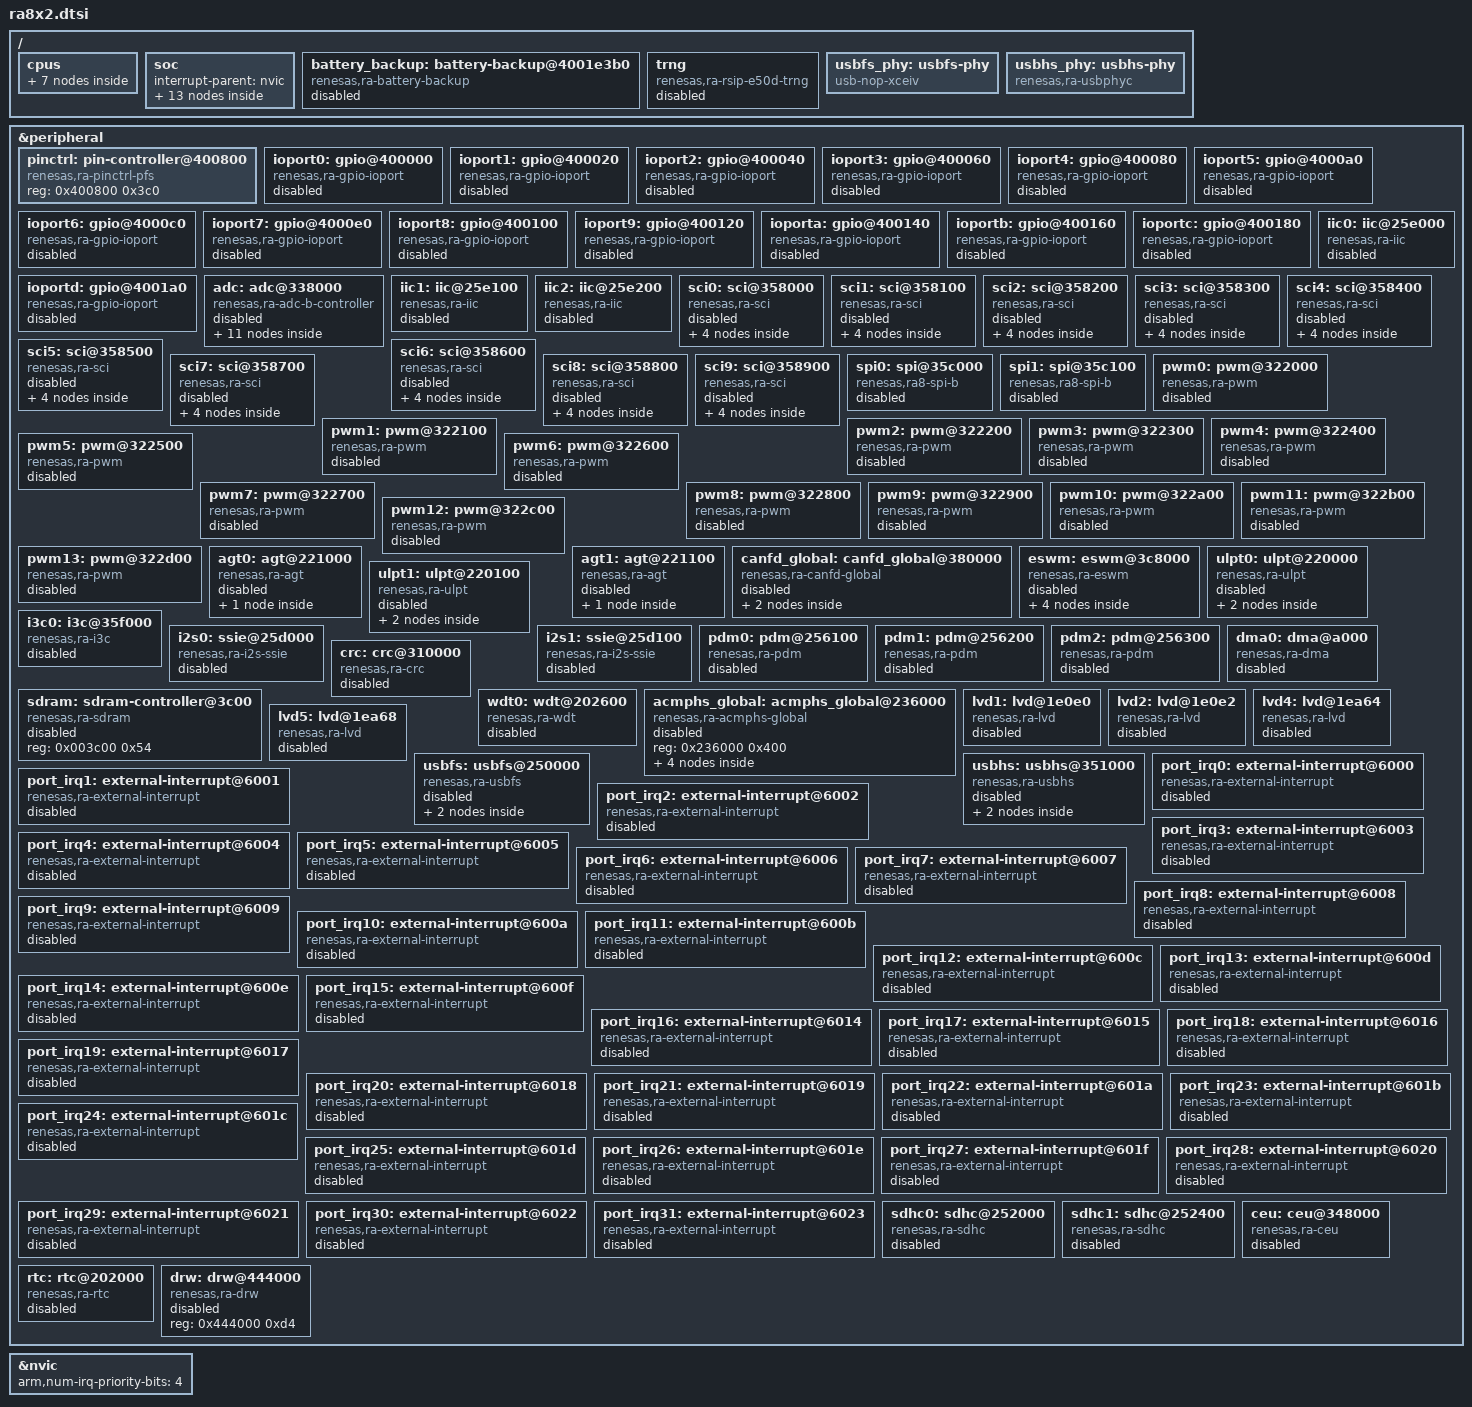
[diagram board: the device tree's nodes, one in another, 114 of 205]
/*
 * Copyright (c) 2025 Renesas Electronics Corporation
 *
 * SPDX-License-Identifier: Apache-2.0
 */

#include <mem.h>
#include <freq.h>
#include <zephyr/dt-bindings/pinctrl/renesas/pinctrl-ra.h>
#include <zephyr/dt-bindings/clock/ra_clock.h>
#include <zephyr/dt-bindings/pwm/ra_pwm.h>
#include <zephyr/dt-bindings/i2c/i2c.h>
#include <zephyr/dt-bindings/adc/renesas-adc-b.h>

/ {
	cpus {
		#address-cells = <1>;
		#size-cells = <0>;

		cpu0: cpu@0 {
			device_type = "cpu";
			compatible = "arm,cortex-m85";
			reg = <0>;
			#address-cells = <1>;
			#size-cells = <1>;
			cpu-power-states = <&stop0 &stop1>;

			mpu: mpu@e000ed90 {
				compatible = "arm,armv8.1m-mpu";
				reg = <0xe000ed90 0x40>;
			};
		};

		cpu1: cpu@1 {
			device_type = "cpu";
			compatible = "arm,cortex-m33";
			reg = <1>;
			#address-cells = <1>;
			#size-cells = <1>;

			mpu: mpu@e000ed90 {
				compatible = "arm,armv8m-mpu";
				reg = <0xe000ed90 0x40>;
			};
		};

		power-states {
			stop0: state0 {
				compatible = "zephyr,power-state";
				power-state-name = "runtime-idle";
				min-residency-us = <100>;
			};

			stop1: state1 {
				compatible = "zephyr,power-state";
				power-state-name = "standby";
				min-residency-us = <5000>;
				exit-latency-us = <3000>;
			};
		};
	};

	soc {
		interrupt-parent = <&nvic>;

		option_setting_ofs_conf_sec: option-setting-ofs-conf-sec@2c9f040 {
			reg = <0x02c9f040 0x3c0>;
			#address-cells = <1>;
			#size-cells = <1>;
			status = "okay";

			option_setting_ofs0: option-setting-ofs0@2c9f040 {
				compatible = "zephyr,memory-region";
				zephyr,memory-region = "OFS_OFS0_MEMORY";
				reg = <0x02c9f040 0x4>;
				status = "okay";
			};

			option_setting_ofs2: option-setting-ofs2@2c9f044 {
				compatible = "zephyr,memory-region";
				zephyr,memory-region = "OFS_OFS2_MEMORY";
				reg = <0x02c9f044 0x4>;
				status = "okay";
			};

			option_setting_sas: option-setting-sas@2c9f074 {
				compatible = "zephyr,memory-region";
				zephyr,memory-region = "OFS_SAS_MEMORY";
				reg = <0x02c9f074 0x4>;
				status = "okay";
			};

			option_setting_ofs1_sec: option-setting-ofs1-sec@2c9f0c0 {
				compatible = "zephyr,memory-region";
				zephyr,memory-region = "OFS_OFS1_SEC_MEMORY";
				reg = <0x02c9f0c0 0x4>;
				status = "okay";
			};

			option_setting_ofs3_sec: option-setting-ofs3-sec@2c9f0c4 {
				compatible = "zephyr,memory-region";
				zephyr,memory-region = "OFS_OFS3_SEC_MEMORY";
				reg = <0x02c9f0c4 0x4>;
				status = "okay";
			};

			option_setting_ofs1_sel: option-setting-ofs1-sel@2c9f120 {
				compatible = "zephyr,memory-region";
				zephyr,memory-region = "OFS_OFS1_SEL_MEMORY";
				reg = <0x02c9f120 0x4>;
				status = "okay";
			};

			option_setting_ofs3_sel: option-setting-ofs3-sel@2c9f124 {
				compatible = "zephyr,memory-region";
				zephyr,memory-region = "OFS_OFS3_SEL_MEMORY";
				reg = <0x02c9f124 0x4>;
				status = "okay";
			};

			option_setting_bps_sec: option-setting-bps-sec@2c9f200 {
				compatible = "zephyr,memory-region";
				zephyr,memory-region = "OFS_BPS_SEC_MEMORY";
				reg = <0x02c9f200 0x200>;
				status = "okay";
			};
		};

		option_setting_ofs_otp_sec: option-setting-ofs-otp-sec@2e07400 {
			reg = <0x02e07400 0x120a30>;
			#address-cells = <1>;
			#size-cells = <1>;
			status = "okay";

			option_setting_otp_pbps_sec: option-setting-otp-pbps-sec@2e17700 {
				compatible = "zephyr,memory-region";
				zephyr,memory-region = "OFS_OTP_PBPS_SEC_MEMORY";
				reg = <0x02e17700 0x80>;
				status = "okay";
			};
		};

		ospi0: ospi@40268000 {
			compatible = "renesas,ra-ospi-b";
			reg = <0x40268000 0x19c>, <0x80000000 DT_SIZE_M(512)>;
			unit = <0>;
			#address-cells = <1>;
			#size-cells = <0>;
			clocks = <&octaspiclk MSTPB 16>;
			status = "disabled";
		};

		ospi1: ospi@40268400 {
			compatible = "renesas,ra-ospi-b";
			reg = <0x40268400 0x19c>, <0x70000000 DT_SIZE_M(256)>;
			unit = <1>;
			#address-cells = <1>;
			#size-cells = <0>;
			clocks = <&octaspiclk MSTPB 17>;
			status = "disabled";
		};
	};

	battery_backup: battery-backup@4001e3b0 {
		compatible = "renesas,ra-battery-backup";
		reg = <0x4001e3b0 0x2>, <0x4001e3d0 0x4>,
		      <0x4001ea84 0x1>, <0x4001ea88 0x1>,
		      <0x4001ec40 0x1>, <0x4001ec45 0x1>,
		      <0x4001ec46 0x1>, <0x4001ec48 0x1>,
		      <0x4001ec49 0x1>, <0x4001ec4a 0x1>,
		      <0x4001ec4c 0x1>, <0x4001ec4d 0x1>,
		      <0x4001ec4e 0x1>, <0x4001ed00 0x80>;
		reg-names = "vbrsabar", "bbfsar",
			    "vbattmnselr", "vbtbpcr1",
			    "vbtber", "vbtbpcr2",
			    "vbtbpsr", "vbtadsr",
			    "vbtadcr1", "vbtadcr2",
			    "vbtictlr", "vbtictlr2",
			    "vbtimonr", "vbtbkrn";
		manual-configure;
		status = "disabled";
	};

	trng: trng {
		compatible = "renesas,ra-rsip-e50d-trng";
		status = "disabled";
	};

	usbfs_phy: usbfs-phy {
		compatible = "usb-nop-xceiv";
		#phy-cells = <0>;
	};

	usbhs_phy: usbhs-phy {
		compatible = "renesas,ra-usbphyc";
		#phy-cells = <0>;
	};
};

&peripheral {
	#address-cells = <1>;
	#size-cells = <1>;

	pinctrl: pin-controller@400800 {
		compatible = "renesas,ra-pinctrl-pfs";
		reg = <0x400800 0x3c0>;
		status = "okay";
	};

	ioport0: gpio@400000 {
		compatible = "renesas,ra-gpio-ioport";
		reg = <0x400000 0x20>;
		port = <0>;
		gpio-controller;
		#gpio-cells = <2>;
		ngpios = <16>;
		status = "disabled";
	};

	ioport1: gpio@400020 {
		compatible = "renesas,ra-gpio-ioport";
		reg = <0x400020 0x20>;
		port = <1>;
		gpio-controller;
		#gpio-cells = <2>;
		ngpios = <16>;
		status = "disabled";
	};

	ioport2: gpio@400040 {
		compatible = "renesas,ra-gpio-ioport";
		reg = <0x400040 0x20>;
		port = <2>;
		gpio-controller;
		#gpio-cells = <2>;
		ngpios = <16>;
		status = "disabled";
	};

	ioport3: gpio@400060 {
		compatible = "renesas,ra-gpio-ioport";
		reg = <0x400060 0x20>;
		port = <3>;
		gpio-controller;
		#gpio-cells = <2>;
		ngpios = <16>;
		status = "disabled";
	};

	ioport4: gpio@400080 {
		compatible = "renesas,ra-gpio-ioport";
		reg = <0x400080 0x20>;
		port = <4>;
		gpio-controller;
		#gpio-cells = <2>;
		ngpios = <16>;
		vbatts-pins = <2 3 4>;
		status = "disabled";
	};

	ioport5: gpio@4000a0 {
		compatible = "renesas,ra-gpio-ioport";
		reg = <0x4000a0 0x20>;
		port = <5>;
		gpio-controller;
		#gpio-cells = <2>;
		ngpios = <16>;
		status = "disabled";
	};

	ioport6: gpio@4000c0 {
		compatible = "renesas,ra-gpio-ioport";
		reg = <0x4000c0 0x20>;
		port = <6>;
		gpio-controller;
		#gpio-cells = <2>;
		ngpios = <16>;
		status = "disabled";
	};

	ioport7: gpio@4000e0 {
		compatible = "renesas,ra-gpio-ioport";
		reg = <0x4000e0 0x20>;
		port = <7>;
		gpio-controller;
		#gpio-cells = <2>;
		ngpios = <16>;
		status = "disabled";
	};

	ioport8: gpio@400100 {
		compatible = "renesas,ra-gpio-ioport";
		reg = <0x400100 0x20>;
		port = <8>;
		gpio-controller;
		#gpio-cells = <2>;
		ngpios = <16>;
		status = "disabled";
	};

	ioport9: gpio@400120 {
		compatible = "renesas,ra-gpio-ioport";
		reg = <0x400120 0x20>;
		port = <9>;
		gpio-controller;
		#gpio-cells = <2>;
		ngpios = <16>;
		status = "disabled";
	};

	ioporta: gpio@400140 {
		compatible = "renesas,ra-gpio-ioport";
		reg = <0x400140 0x20>;
		port = <10>;
		gpio-controller;
		#gpio-cells = <2>;
		ngpios = <16>;
		status = "disabled";
	};

	ioportb: gpio@400160 {
		compatible = "renesas,ra-gpio-ioport";
		reg = <0x400160 0x20>;
		port = <11>;
		gpio-controller;
		#gpio-cells = <2>;
		ngpios = <8>;
		status = "disabled";
	};

	ioportc: gpio@400180 {
		compatible = "renesas,ra-gpio-ioport";
		reg = <0x400180 0x20>;
		port = <12>;
		gpio-controller;
		#gpio-cells = <2>;
		ngpios = <16>;
		status = "disabled";
	};

	ioportd: gpio@4001a0 {
		compatible = "renesas,ra-gpio-ioport";
		reg = <0x4001a0 0x20>;
		port = <13>;
		gpio-controller;
		#gpio-cells = <2>;
		ngpios = <8>;
		status = "disabled";
	};

	adc: adc@338000 {
		compatible = "renesas,ra-adc-b-controller";
		reg = <0x338000 0x2224>;
		clocks = <&pclka MSTPD 21>;
		clock-div = <3>;
		#io-channel-cells = <1>;
		#address-cells = <1>;
		#size-cells = <0>;
		status = "disabled";

		scan_group0: scan-group@0 {
			compatible = "renesas,ra-adc-b-scan-group";
			reg = <0>;
			status = "disabled";
		};

		scan_group1: scan-group@1 {
			compatible = "renesas,ra-adc-b-scan-group";
			reg = <1>;
			status = "disabled";
		};

		scan_group2: scan-group@2 {
			compatible = "renesas,ra-adc-b-scan-group";
			reg = <2>;
			status = "disabled";
		};

		scan_group3: scan-group@3 {
			compatible = "renesas,ra-adc-b-scan-group";
			reg = <3>;
			status = "disabled";
		};

		scan_group4: scan-group@4 {
			compatible = "renesas,ra-adc-b-scan-group";
			reg = <4>;
			status = "disabled";
		};

		scan_group5: scan-group@5 {
			compatible = "renesas,ra-adc-b-scan-group";
			reg = <5>;
			status = "disabled";
		};

		scan_group6: scan-group@6 {
			compatible = "renesas,ra-adc-b-scan-group";
			reg = <6>;
			status = "disabled";
		};

		scan_group7: scan-group@7 {
			compatible = "renesas,ra-adc-b-scan-group";
			reg = <7>;
			status = "disabled";
		};

		scan_group8: scan-group@8 {
			compatible = "renesas,ra-adc-b-scan-group";
			reg = <8>;
			status = "disabled";
		};

		adc0: adc-unit0 {
			compatible = "renesas,ra-adc-b";
			unit-id = <0>;
			channel-available-mask = <0x7f503f>; /* 0-5, 12, 14, 16-22 */
			vref-mv = <3300>;
			#io-channel-cells = <1>;
			#address-cells = <1>;
			#size-cells = <0>;
			status = "disabled";
		};

		adc1: adc-unit1 {
			compatible = "renesas,ra-adc-b";
			unit-id = <1>;
			channel-available-mask = <0x7fafc0>; /* 6-11, 13, 15, 16-22 */
			vref-mv = <3300>;
			#io-channel-cells = <1>;
			#address-cells = <1>;
			#size-cells = <0>;
			status = "disabled";
		};
	};

	iic0: iic@25e000 {
		compatible = "renesas,ra-iic";
		channel = <0>;
		reg = <0x25e000 0x100>;
		clocks = <&pclkb MSTPB 9>;
		status = "disabled";
	};

	iic1: iic@25e100 {
		compatible = "renesas,ra-iic";
		channel = <1>;
		reg = <0x25e100 0x100>;
		clocks = <&pclkb MSTPB 8>;
		status = "disabled";
	};

	iic2: iic@25e200 {
		compatible = "renesas,ra-iic";
		channel = <2>;
		reg = <0x25e200 0x100>;
		clocks = <&pclkb MSTPB 7>;
		status = "disabled";
	};

	sci0: sci@358000 {
		compatible = "renesas,ra-sci";
		reg = <0x358000 0x100>;
		channel = <0>;
		clocks = <&sciclk MSTPB 31>;
		status = "disabled";

		uart {
			compatible = "renesas,ra8-uart-sci-b";
			channel = <0>;
			status = "disabled";
		};

		i2c {
			compatible = "renesas,ra-i2c-sci-b";
			#address-cells = <1>;
			#size-cells = <0>;
			channel = <0>;
			status = "disabled";
		};

		spi {
			compatible = "renesas,ra-spi-sci-b";
			#address-cells = <1>;
			#size-cells = <0>;
			channel = <0>;
			overrun-character = <0x00>;
			status = "disabled";
		};

		lin {
			compatible = "renesas,ra-lin-sci-b";
			status = "disabled";
		};
	};

	sci1: sci@358100 {
		compatible = "renesas,ra-sci";
		reg = <0x358100 0x100>;
		channel = <1>;
		clocks = <&sciclk MSTPB 30>;
		status = "disabled";

		uart {
			compatible = "renesas,ra8-uart-sci-b";
			channel = <1>;
			status = "disabled";
		};

		i2c {
			compatible = "renesas,ra-i2c-sci-b";
			#address-cells = <1>;
			#size-cells = <0>;
			channel = <1>;
			status = "disabled";
		};

		spi {
			compatible = "renesas,ra-spi-sci-b";
			#address-cells = <1>;
			#size-cells = <0>;
			channel = <1>;
			overrun-character = <0x00>;
			status = "disabled";
		};

		lin {
			compatible = "renesas,ra-lin-sci-b";
			status = "disabled";
		};
	};

	sci2: sci@358200 {
		compatible = "renesas,ra-sci";
		reg = <0x358200 0x100>;
		channel = <2>;
		clocks = <&sciclk MSTPB 29>;
		status = "disabled";

		uart {
			compatible = "renesas,ra8-uart-sci-b";
			channel = <2>;
			status = "disabled";
		};

		i2c {
			compatible = "renesas,ra-i2c-sci-b";
			#address-cells = <1>;
			#size-cells = <0>;
			channel = <2>;
			status = "disabled";
		};

		spi {
			compatible = "renesas,ra-spi-sci-b";
			#address-cells = <1>;
			#size-cells = <0>;
			channel = <2>;
			overrun-character = <0x00>;
			status = "disabled";
		};

		lin {
			compatible = "renesas,ra-lin-sci-b";
			status = "disabled";
		};
	};

	sci3: sci@358300 {
		compatible = "renesas,ra-sci";
		reg = <0x358300 0x100>;
		channel = <3>;
		clocks = <&sciclk MSTPB 28>;
		status = "disabled";

		uart {
			compatible = "renesas,ra8-uart-sci-b";
			channel = <3>;
			status = "disabled";
		};

		i2c {
			compatible = "renesas,ra-i2c-sci-b";
			#address-cells = <1>;
			#size-cells = <0>;
			channel = <3>;
			status = "disabled";
		};

		spi {
			compatible = "renesas,ra-spi-sci-b";
			#address-cells = <1>;
			#size-cells = <0>;
			channel = <3>;
			overrun-character = <0x00>;
			status = "disabled";
		};

		lin {
			compatible = "renesas,ra-lin-sci-b";
			status = "disabled";
		};
	};

	sci4: sci@358400 {
		compatible = "renesas,ra-sci";
		reg = <0x358400 0x100>;
		channel = <4>;
		clocks = <&sciclk MSTPB 27>;
		status = "disabled";

		uart {
			compatible = "renesas,ra8-uart-sci-b";
			channel = <4>;
			status = "disabled";
		};

		i2c {
			compatible = "renesas,ra-i2c-sci-b";
			#address-cells = <1>;
			#size-cells = <0>;
			channel = <4>;
			status = "disabled";
		};

		spi {
			compatible = "renesas,ra-spi-sci-b";
			#address-cells = <1>;
			#size-cells = <0>;
			channel = <4>;
			overrun-character = <0x00>;
			status = "disabled";
		};

		lin {
			compatible = "renesas,ra-lin-sci-b";
			status = "disabled";
		};
	};

	sci5: sci@358500 {
		compatible = "renesas,ra-sci";
		reg = <0x358500 0x100>;
		channel = <5>;
		clocks = <&sciclk MSTPB 26>;
		status = "disabled";

		uart {
			compatible = "renesas,ra8-uart-sci-b";
			channel = <5>;
			status = "disabled";
		};

		i2c {
			compatible = "renesas,ra-i2c-sci-b";
			#address-cells = <1>;
			#size-cells = <0>;
			channel = <5>;
			status = "disabled";
		};

		spi {
			compatible = "renesas,ra-spi-sci-b";
			#address-cells = <1>;
			#size-cells = <0>;
			channel = <5>;
			overrun-character = <0x00>;
			status = "disabled";
		};

		lin {
			compatible = "renesas,ra-lin-sci-b";
			status = "disabled";
		};
	};

	sci6: sci@358600 {
		compatible = "renesas,ra-sci";
		reg = <0x358600 0x100>;
		channel = <6>;
		clocks = <&sciclk MSTPB 25>;
		status = "disabled";

		uart {
			compatible = "renesas,ra8-uart-sci-b";
			channel = <6>;
			status = "disabled";
		};

		i2c {
			compatible = "renesas,ra-i2c-sci-b";
			#address-cells = <1>;
			#size-cells = <0>;
			channel = <6>;
			status = "disabled";
		};

		spi {
			compatible = "renesas,ra-spi-sci-b";
			#address-cells = <1>;
			#size-cells = <0>;
			channel = <6>;
			overrun-character = <0x00>;
			status = "disabled";
		};

		lin {
			compatible = "renesas,ra-lin-sci-b";
			status = "disabled";
		};
	};

	sci7: sci@358700 {
		compatible = "renesas,ra-sci";
		reg = <0x358700 0x100>;
		channel = <7>;
		clocks = <&sciclk MSTPB 24>;
		status = "disabled";

		uart {
			compatible = "renesas,ra8-uart-sci-b";
			channel = <7>;
			status = "disabled";
		};

		i2c {
			compatible = "renesas,ra-i2c-sci-b";
			#address-cells = <1>;
			#size-cells = <0>;
			channel = <7>;
			status = "disabled";
		};

		spi {
			compatible = "renesas,ra-spi-sci-b";
			#address-cells = <1>;
			#size-cells = <0>;
			channel = <7>;
			overrun-character = <0x00>;
			status = "disabled";
		};

		lin {
			compatible = "renesas,ra-lin-sci-b";
			status = "disabled";
		};
	};

	sci8: sci@358800 {
		compatible = "renesas,ra-sci";
		reg = <0x358800 0x100>;
		channel = <8>;
		clocks = <&sciclk MSTPB 23>;
		status = "disabled";

		uart {
			compatible = "renesas,ra8-uart-sci-b";
			channel = <8>;
			status = "disabled";
		};

		i2c {
			compatible = "renesas,ra-i2c-sci-b";
			#address-cells = <1>;
			#size-cells = <0>;
			channel = <8>;
			status = "disabled";
		};

		spi {
			compatible = "renesas,ra-spi-sci-b";
			#address-cells = <1>;
			#size-cells = <0>;
			channel = <8>;
			overrun-character = <0x00>;
			status = "disabled";
		};

		lin {
			compatible = "renesas,ra-lin-sci-b";
			status = "disabled";
		};
	};

	sci9: sci@358900 {
		compatible = "renesas,ra-sci";
		reg = <0x358900 0x100>;
		channel = <9>;
		clocks = <&sciclk MSTPB 22>;
		status = "disabled";

		uart {
			compatible = "renesas,ra8-uart-sci-b";
			channel = <9>;
			status = "disabled";
		};

		i2c {
			compatible = "renesas,ra-i2c-sci-b";
			#address-cells = <1>;
			#size-cells = <0>;
			channel = <9>;
			status = "disabled";
		};

		spi {
			compatible = "renesas,ra-spi-sci-b";
			#address-cells = <1>;
			#size-cells = <0>;
			channel = <9>;
			overrun-character = <0x00>;
			status = "disabled";
		};

		lin {
			compatible = "renesas,ra-lin-sci-b";
			status = "disabled";
		};
	};

	spi0: spi@35c000 {
		compatible = "renesas,ra8-spi-b";
		#address-cells = <1>;
		#size-cells = <0>;
		channel = <0>;
		clocks = <&pclka MSTPB 19>;
		clock-names = "spiclk";
		reg = <0x35c000 0x100>;
		status = "disabled";
	};

	spi1: spi@35c100 {
		compatible = "renesas,ra8-spi-b";
		#address-cells = <1>;
		#size-cells = <0>;
		channel = <1>;
		clocks = <&pclka MSTPB 18>;
		clock-names = "spiclk";
		reg = <0x35c100 0x100>;
		status = "disabled";
	};

	pwm0: pwm@322000 {
		compatible = "renesas,ra-pwm";
		divider = <RA_PWM_SOURCE_DIV_1>;
		channel = <RA_PWM_CHANNEL_0>;
		clocks = <&gptclk MSTPE 31>;
		reg = <0x322000 0x100>;
		#pwm-cells = <3>;
		status = "disabled";
	};

	pwm1: pwm@322100 {
		compatible = "renesas,ra-pwm";
		divider = <RA_PWM_SOURCE_DIV_1>;
		channel = <RA_PWM_CHANNEL_1>;
		clocks = <&gptclk MSTPE 30>;
		reg = <0x322100 0x100>;
		#pwm-cells = <3>;
		status = "disabled";
	};

	pwm2: pwm@322200 {
		compatible = "renesas,ra-pwm";
		divider = <RA_PWM_SOURCE_DIV_1>;
		channel = <RA_PWM_CHANNEL_2>;
		clocks = <&gptclk MSTPE 29>;
		reg = <0x322200 0x100>;
		#pwm-cells = <3>;
		status = "disabled";
	};

	pwm3: pwm@322300 {
		compatible = "renesas,ra-pwm";
		divider = <RA_PWM_SOURCE_DIV_1>;
		channel = <RA_PWM_CHANNEL_3>;
		clocks = <&gptclk MSTPE 28>;
		reg = <0x322300 0x100>;
		#pwm-cells = <3>;
		status = "disabled";
	};

	pwm4: pwm@322400 {
		compatible = "renesas,ra-pwm";
		divider = <RA_PWM_SOURCE_DIV_1>;
		channel = <RA_PWM_CHANNEL_4>;
		clocks = <&gptclk MSTPE 27>;
		reg = <0x322400 0x100>;
		#pwm-cells = <3>;
		status = "disabled";
	};

	pwm5: pwm@322500 {
		compatible = "renesas,ra-pwm";
		divider = <RA_PWM_SOURCE_DIV_1>;
		channel = <RA_PWM_CHANNEL_5>;
		clocks = <&gptclk MSTPE 27>;
		reg = <0x322500 0x100>;
		#pwm-cells = <3>;
		status = "disabled";
	};

	pwm6: pwm@322600 {
		compatible = "renesas,ra-pwm";
		divider = <RA_PWM_SOURCE_DIV_1>;
		channel = <RA_PWM_CHANNEL_6>;
		clocks = <&gptclk MSTPE 27>;
		reg = <0x322600 0x100>;
		#pwm-cells = <3>;
		status = "disabled";
	};

	pwm7: pwm@322700 {
		compatible = "renesas,ra-pwm";
		divider = <RA_PWM_SOURCE_DIV_1>;
		channel = <RA_PWM_CHANNEL_7>;
		clocks = <&gptclk MSTPE 27>;
		reg = <0x322700 0x100>;
		#pwm-cells = <3>;
		status = "disabled";
	};

	pwm8: pwm@322800 {
		compatible = "renesas,ra-pwm";
		divider = <RA_PWM_SOURCE_DIV_1>;
		channel = <RA_PWM_CHANNEL_8>;
		clocks = <&gptclk MSTPE 27>;
		reg = <0x322800 0x100>;
		#pwm-cells = <3>;
		status = "disabled";
	};

	pwm9: pwm@322900 {
		compatible = "renesas,ra-pwm";
		divider = <RA_PWM_SOURCE_DIV_1>;
		channel = <RA_PWM_CHANNEL_9>;
		clocks = <&gptclk MSTPE 27>;
		reg = <0x322900 0x100>;
		#pwm-cells = <3>;
		status = "disabled";
	};

	pwm10: pwm@322a00 {
		compatible = "renesas,ra-pwm";
		divider = <RA_PWM_SOURCE_DIV_1>;
		channel = <RA_PWM_CHANNEL_10>;
		clocks = <&gptclk MSTPE 21>;
		reg = <0x322a00 0x100>;
		#pwm-cells = <3>;
		status = "disabled";
	};

	pwm11: pwm@322b00 {
		compatible = "renesas,ra-pwm";
		divider = <RA_PWM_SOURCE_DIV_1>;
		channel = <RA_PWM_CHANNEL_11>;
		clocks = <&gptclk MSTPE 20>;
		reg = <0x322b00 0x100>;
		#pwm-cells = <3>;
		status = "disabled";
	};

	pwm12: pwm@322c00 {
		compatible = "renesas,ra-pwm";
		divider = <RA_PWM_SOURCE_DIV_1>;
		channel = <RA_PWM_CHANNEL_12>;
		clocks = <&gptclk MSTPE 19>;
		reg = <0x322c00 0x100>;
		#pwm-cells = <3>;
		status = "disabled";
	};

	pwm13: pwm@322d00 {
		compatible = "renesas,ra-pwm";
		divider = <RA_PWM_SOURCE_DIV_1>;
		channel = <RA_PWM_CHANNEL_13>;
		clocks = <&gptclk MSTPE 18>;
		reg = <0x322d00 0x100>;
		#pwm-cells = <3>;
		status = "disabled";
	};

	agt0: agt@221000 {
		compatible = "renesas,ra-agt";
		channel = <0>;
		reg = <0x221000 0x100>;
		renesas,count-source = "AGT_CLOCK_LOCO";
		renesas,prescaler = <0>;
		renesas,resolution = <16>;
		status = "disabled";

		counter {
			compatible = "renesas,ra-agt-counter";
			status = "disabled";
		};
	};

	agt1: agt@221100 {
		compatible = "renesas,ra-agt";
		channel = <1>;
		reg = <0x221100 0x100>;
		renesas,count-source = "AGT_CLOCK_LOCO";
		renesas,prescaler = <0>;
		renesas,resolution = <16>;
		status = "disabled";

		counter {
			compatible = "renesas,ra-agt-counter";
			status = "disabled";
		};
	};

	canfd_global: canfd_global@380000 {
		compatible = "renesas,ra-canfd-global";
		clocks = <&pclka 0 0>, <&pclke 0 0>;
		clock-names = "opclk", "ramclk";
		dll-min-freq = <DT_FREQ_M(8)>;
		dll-max-freq = <DT_FREQ_M(80)>;
		reg = <0x380000 0x4000>;
		status = "disabled";

		canfd0: canfd0 {
			compatible = "renesas,ra-canfd";
			channel = <0>;
			clocks = <&canfdclk MSTPC 27>;
			clock-names = "dllclk";
			status = "disabled";
		};

		canfd1: canfd1 {
			compatible = "renesas,ra-canfd";
			channel = <1>;
			clocks = <&canfdclk MSTPC 26>;
			clock-names = "dllclk";
			status = "disabled";
		};
	};

	eswm: eswm@3c8000 {
		compatible = "renesas,ra-eswm";
		reg = <0x3c8000 0x19424>;
		clocks = <&iclk 0 0>,
			 <&pclka MSTPC 30>,
			 <&eswclk 0 0>,
			 <&eswphyclk 0 0>,
			 <&ethphyclk MSTPC 28>;
		clock-names = "gwcaclk", "pclk", "eswclk", "eswphyclk", "ethphyclk";
		#address-cells = <1>;
		#size-cells = <1>;
		ranges;
		status = "disabled";

		eth0: ethernet_mac@3cb000 {
			compatible = "renesas,ra-ethernet-rmac";
			reg = <0x3cb000 0x530>;
			channel = <0>;
			status = "disabled";
		};

		eth1: ethernet_mac@3cd000 {
			compatible = "renesas,ra-ethernet-rmac";
			reg = <0x3cd000 0x530>;
			channel = <1>;
			status = "disabled";
		};

		mdio0: mdio@3cb000 {
			compatible = "renesas,ra-mdio-rmac";
			reg = <0x3cb000 0x4>, <0x3cb004 0x4>;
			reg-names = "mpsm", "mpic";
			#address-cells = <1>;
			#size-cells = <0>;
			channel = <0>;
			status = "disabled";
		};

		mdio1: mdio@3cd000 {
			compatible = "renesas,ra-mdio-rmac";
			reg = <0x3cd000 0x4>, <0x3cd004 0x4>;
			reg-names = "mpsm", "mpic";
			#address-cells = <1>;
			#size-cells = <0>;
			channel = <1>;
			status = "disabled";
		};
	};

	ulpt0: ulpt@220000 {
		compatible = "renesas,ra-ulpt";
		reg = <0x220000 0x100>;
		channel = <0>;
		count-source = "ULPT_CLOCK_LOCO";
		prescaler = <0>;
		status = "disabled";

		timer {
			compatible = "renesas,ra-ulpt-timer";
			status = "disabled";
		};

		counter {
			compatible = "renesas,ra-ulpt-counter";
			status = "disabled";
		};
	};

	ulpt1: ulpt@220100 {
		compatible = "renesas,ra-ulpt";
		reg = <0x220100 0x100>;
		channel = <1>;
		count-source = "ULPT_CLOCK_LOCO";
		prescaler = <0>;
		status = "disabled";

		timer {
			compatible = "renesas,ra-ulpt-timer";
			status = "disabled";
		};

		counter {
			compatible = "renesas,ra-ulpt-counter";
			status = "disabled";
		};
	};

	i3c0: i3c@35f000 {
		compatible = "renesas,ra-i3c";
		#address-cells = <3>;
		#size-cells = <0>;
		reg = <0x35f000 0x3e8>;
		channel = <0>;
		clocks = <&pclka MSTPB 4>, <&i3cclk 0 0>;
		clock-names = "pclk", "tclk";
		status = "disabled";
	};

	i2s0: ssie@25d000 {
		compatible = "renesas,ra-i2s-ssie";
		#address-cells = <1>;
		#size-cells = <0>;
		channel = <0>;
		reg = <0x25d000 0x28>;
		clocks = <&pclkb MSTPC 8>;
		clock-names = "pclk";
		full-duplex;
		status = "disabled";
	};

	i2s1: ssie@25d100 {
		compatible = "renesas,ra-i2s-ssie";
		#address-cells = <1>;
		#size-cells = <0>;
		channel = <1>;
		reg = <0x25d100 0x28>;
		clocks = <&pclkb MSTPC 7>;
		clock-names = "pclk";
		status = "disabled";
	};

	pdm0: pdm@256100 {
		compatible = "renesas,ra-pdm";
		reg = <0x256100 0x100>;
		channel = <0>;
		clocks = <&pclkb MSTPC 24>, <&moco>;
		clock-names = "pclk", "pdmifclk";
		status = "disabled";
	};

	pdm1: pdm@256200 {
		compatible = "renesas,ra-pdm";
		reg = <0x256200 0x100>;
		channel = <1>;
		clocks = <&pclkb MSTPC 24>, <&moco>;
		clock-names = "pclk", "pdmifclk";
		status = "disabled";
	};

	pdm2: pdm@256300 {
		compatible = "renesas,ra-pdm";
		reg = <0x256300 0x100>;
		channel = <2>;
		clocks = <&pclkb MSTPC 24>, <&moco>;
		clock-names = "pclk", "pdmifclk";
		status = "disabled";
	};

	sdram: sdram-controller@3c00 {
		compatible = "renesas,ra-sdram";
		#address-cells = <1>;
		#size-cells = <0>;
		reg = <0x003c00 0x54>;
		status = "disabled";
	};

	dma0: dma@a000 {
		compatible = "renesas,ra-dma";
		reg = <0x00a000 0x34>, <0x00a800 0xa0>;
		reg-names = "channel", "common";
		clocks = <&iclk MSTPA 22>;
		dma-channels = <8>;
		#dma-cells = <1>;
		status = "disabled";
	};

	crc: crc@310000 {
		compatible = "renesas,ra-crc";
		reg = <0x310000 0x10>;
		clocks = <&pclka MSTPC 1>;
		status = "disabled";
	};

	wdt0: wdt@202600 {
		compatible = "renesas,ra-wdt";
		reg = <0x202600 0x12>;
		clocks = <&pclkb 0 0>;
		status = "disabled";
	};

	acmphs_global: acmphs_global@236000 {
		compatible = "renesas,ra-acmphs-global";
		reg = <0x236000 0x400>;
		status = "disabled";

		acmphs0: acmphs0 {
			compatible = "renesas,ra-acmphs";
			channel = <0>;
			status = "disabled";
		};

		acmphs1: acmphs1 {
			compatible = "renesas,ra-acmphs";
			channel = <1>;
			status = "disabled";
		};

		acmphs2: acmphs2 {
			compatible = "renesas,ra-acmphs";
			channel = <2>;
			status = "disabled";
		};

		acmphs3: acmphs3 {
			compatible = "renesas,ra-acmphs";
			channel = <3>;
			status = "disabled";
		};
	};

	lvd1: lvd@1e0e0 {
		compatible = "renesas,ra-lvd";
		reg = <0x01e0e0 0x02>;
		channel = <1>;
		status = "disabled";
	};

	lvd2: lvd@1e0e2 {
		compatible = "renesas,ra-lvd";
		reg = <0x01e0e2 0x02>;
		channel = <2>;
		status = "disabled";
	};

	lvd4: lvd@1ea64 {
		compatible = "renesas,ra-lvd";
		reg = <0x01ea64 0x02>;
		channel = <4>;
		reset-only;
		status = "disabled";
	};

	lvd5: lvd@1ea68 {
		compatible = "renesas,ra-lvd";
		reg = <0x01ea68 0x02>;
		channel = <5>;
		reset-only;
		status = "disabled";
	};

	usbfs: usbfs@250000 {
		compatible = "renesas,ra-usbfs";
		reg = <0x250000 0x2000>;
		num-bidir-endpoints = <10>;
		phys = <&usbfs_phy>;
		phys-clock = <&uclk>;
		status = "disabled";

		udc {
			compatible = "renesas,ra-udc";
			status = "disabled";
		};

		uhc {
			compatible = "renesas,ra-uhc";
			status = "disabled";
		};
	};

	usbhs: usbhs@351000 {
		compatible = "renesas,ra-usbhs";
		reg = <0x351000 0x2000>;
		num-bidir-endpoints = <10>;
		phys = <&usbhs_phy>;
		phys-clock = <&uclk>, <&usb60clk>;
		status = "disabled";

		udc {
			compatible = "renesas,ra-udc";
			status = "disabled";
		};

		uhc {
			compatible = "renesas,ra-uhc";
			status = "disabled";
		};
	};

	port_irq0: external-interrupt@6000 {
		compatible = "renesas,ra-external-interrupt";
		reg = <0x006000 0x1>;
		channel = <0>;
		renesas,sample-clock-div = <64>;
		#port-irq-cells = <0>;
		status = "disabled";
	};

	port_irq1: external-interrupt@6001 {
		compatible = "renesas,ra-external-interrupt";
		reg = <0x006001 0x1>;
		channel = <1>;
		renesas,sample-clock-div = <64>;
		#port-irq-cells = <0>;
		status = "disabled";
	};

	port_irq2: external-interrupt@6002 {
		compatible = "renesas,ra-external-interrupt";
		reg = <0x006002 0x1>;
		channel = <2>;
		renesas,sample-clock-div = <64>;
		#port-irq-cells = <0>;
		status = "disabled";
	};

	port_irq3: external-interrupt@6003 {
		compatible = "renesas,ra-external-interrupt";
		reg = <0x006003 0x1>;
		channel = <3>;
		renesas,sample-clock-div = <64>;
		#port-irq-cells = <0>;
		status = "disabled";
	};

	port_irq4: external-interrupt@6004 {
		compatible = "renesas,ra-external-interrupt";
		reg = <0x006004 0x1>;
		channel = <4>;
		renesas,sample-clock-div = <64>;
		#port-irq-cells = <0>;
		status = "disabled";
	};

	port_irq5: external-interrupt@6005 {
		compatible = "renesas,ra-external-interrupt";
		reg = <0x006005 0x1>;
		channel = <5>;
		renesas,sample-clock-div = <64>;
		#port-irq-cells = <0>;
		status = "disabled";
	};

	port_irq6: external-interrupt@6006 {
		compatible = "renesas,ra-external-interrupt";
		reg = <0x006006 0x1>;
		channel = <6>;
		renesas,sample-clock-div = <64>;
		#port-irq-cells = <0>;
		status = "disabled";
	};

	port_irq7: external-interrupt@6007 {
		compatible = "renesas,ra-external-interrupt";
		reg = <0x006007 0x1>;
		channel = <7>;
		renesas,sample-clock-div = <64>;
		#port-irq-cells = <0>;
		status = "disabled";
	};

	port_irq8: external-interrupt@6008 {
		compatible = "renesas,ra-external-interrupt";
		reg = <0x006008 0x1>;
		channel = <8>;
		renesas,sample-clock-div = <64>;
		#port-irq-cells = <0>;
		status = "disabled";
	};

	port_irq9: external-interrupt@6009 {
		compatible = "renesas,ra-external-interrupt";
		reg = <0x006009 0x1>;
		channel = <9>;
		renesas,sample-clock-div = <64>;
		#port-irq-cells = <0>;
		status = "disabled";
	};

	port_irq10: external-interrupt@600a {
		compatible = "renesas,ra-external-interrupt";
		reg = <0x00600a 0x1>;
		channel = <10>;
		renesas,sample-clock-div = <64>;
		#port-irq-cells = <0>;
		status = "disabled";
	};

	port_irq11: external-interrupt@600b {
		compatible = "renesas,ra-external-interrupt";
		reg = <0x00600b 0x1>;
		channel = <11>;
		renesas,sample-clock-div = <64>;
		#port-irq-cells = <0>;
		status = "disabled";
	};

	port_irq12: external-interrupt@600c {
		compatible = "renesas,ra-external-interrupt";
		reg = <0x00600c 0x1>;
		channel = <12>;
		renesas,sample-clock-div = <64>;
		#port-irq-cells = <0>;
		status = "disabled";
	};

	port_irq13: external-interrupt@600d {
		compatible = "renesas,ra-external-interrupt";
		reg = <0x00600d 0x1>;
		channel = <13>;
		renesas,sample-clock-div = <64>;
		#port-irq-cells = <0>;
		status = "disabled";
	};

	port_irq14: external-interrupt@600e {
		compatible = "renesas,ra-external-interrupt";
		reg = <0x00600e 0x1>;
		channel = <14>;
		renesas,sample-clock-div = <64>;
		#port-irq-cells = <0>;
		status = "disabled";
	};

	port_irq15: external-interrupt@600f {
		compatible = "renesas,ra-external-interrupt";
		reg = <0x00600f 0x1>;
		channel = <15>;
		renesas,sample-clock-div = <64>;
		#port-irq-cells = <0>;
		status = "disabled";
	};

	port_irq16: external-interrupt@6014 {
		compatible = "renesas,ra-external-interrupt";
		reg = <0x006014 0x1>;
		channel = <16>;
		renesas,sample-clock-div = <64>;
		#port-irq-cells = <0>;
		status = "disabled";
	};

	port_irq17: external-interrupt@6015 {
		compatible = "renesas,ra-external-interrupt";
		reg = <0x006015 0x1>;
		channel = <17>;
		renesas,sample-clock-div = <64>;
		#port-irq-cells = <0>;
		status = "disabled";
	};

	port_irq18: external-interrupt@6016 {
		compatible = "renesas,ra-external-interrupt";
		reg = <0x006016 0x1>;
		channel = <18>;
		renesas,sample-clock-div = <64>;
		#port-irq-cells = <0>;
		status = "disabled";
	};

	port_irq19: external-interrupt@6017 {
		compatible = "renesas,ra-external-interrupt";
		reg = <0x006017 0x1>;
		channel = <19>;
		renesas,sample-clock-div = <64>;
		#port-irq-cells = <0>;
		status = "disabled";
	};

	port_irq20: external-interrupt@6018 {
		compatible = "renesas,ra-external-interrupt";
		reg = <0x006018 0x1>;
		channel = <20>;
		renesas,sample-clock-div = <64>;
		#port-irq-cells = <0>;
		status = "disabled";
	};

	port_irq21: external-interrupt@6019 {
		compatible = "renesas,ra-external-interrupt";
		reg = <0x006019 0x1>;
		channel = <21>;
		renesas,sample-clock-div = <64>;
		#port-irq-cells = <0>;
		status = "disabled";
	};

	port_irq22: external-interrupt@601a {
		compatible = "renesas,ra-external-interrupt";
		reg = <0x00601a 0x1>;
		channel = <22>;
		renesas,sample-clock-div = <64>;
		#port-irq-cells = <0>;
		status = "disabled";
	};

	port_irq23: external-interrupt@601b {
		compatible = "renesas,ra-external-interrupt";
		reg = <0x00601b 0x1>;
		channel = <23>;
		renesas,sample-clock-div = <64>;
		#port-irq-cells = <0>;
		status = "disabled";
	};

	port_irq24: external-interrupt@601c {
		compatible = "renesas,ra-external-interrupt";
		reg = <0x00601c 0x1>;
		channel = <24>;
		renesas,sample-clock-div = <64>;
		#port-irq-cells = <0>;
		status = "disabled";
	};

	port_irq25: external-interrupt@601d {
		compatible = "renesas,ra-external-interrupt";
		reg = <0x00601d 0x1>;
		channel = <25>;
		renesas,sample-clock-div = <64>;
		#port-irq-cells = <0>;
		status = "disabled";
	};

	port_irq26: external-interrupt@601e {
		compatible = "renesas,ra-external-interrupt";
		reg = <0x00601e 0x1>;
		channel = <26>;
		renesas,sample-clock-div = <64>;
		#port-irq-cells = <0>;
		status = "disabled";
	};

	port_irq27: external-interrupt@601f {
		compatible = "renesas,ra-external-interrupt";
		reg = <0x00601f 0x1>;
		channel = <27>;
		renesas,sample-clock-div = <64>;
		#port-irq-cells = <0>;
		status = "disabled";
	};

	port_irq28: external-interrupt@6020 {
		compatible = "renesas,ra-external-interrupt";
		reg = <0x006020 0x1>;
		channel = <28>;
		renesas,sample-clock-div = <64>;
		#port-irq-cells = <0>;
		status = "disabled";
	};

	port_irq29: external-interrupt@6021 {
		compatible = "renesas,ra-external-interrupt";
		reg = <0x006021 0x1>;
		channel = <29>;
		renesas,sample-clock-div = <64>;
		#port-irq-cells = <0>;
		status = "disabled";
	};

	port_irq30: external-interrupt@6022 {
		compatible = "renesas,ra-external-interrupt";
		reg = <0x006022 0x1>;
		channel = <30>;
		renesas,sample-clock-div = <64>;
		#port-irq-cells = <0>;
		status = "disabled";
	};

	port_irq31: external-interrupt@6023 {
		compatible = "renesas,ra-external-interrupt";
		reg = <0x006023 0x1>;
		channel = <31>;
		renesas,sample-clock-div = <64>;
		#port-irq-cells = <0>;
		status = "disabled";
	};

	sdhc0: sdhc@252000 {
		compatible = "renesas,ra-sdhc";
		channel = <0>;
		bus-width = <4>;
		sd-support;
		card-detect;
		max-bus-freq = <DT_FREQ_M(52)>;
		clocks = <&pclkb MSTPC 12>;
		reg = <0x252000 0x0400>;
		status = "disabled";
	};

	sdhc1: sdhc@252400 {
		compatible = "renesas,ra-sdhc";
		channel = <1>;
		bus-width = <4>;
		sd-support;
		card-detect;
		max-bus-freq = <DT_FREQ_M(52)>;
		clocks = <&pclkb MSTPC 11>;
		reg = <0x252400 0x0400>;
		status = "disabled";
	};

	ceu: ceu@348000 {
		compatible = "renesas,ra-ceu";
		reg = <0x348000 0x8000>;
		clocks = <&pclka MSTPC 16>;
		clock-names = "pclk";
		status = "disabled";
	};

	rtc: rtc@202000 {
		compatible = "renesas,ra-rtc";
		reg = <0x202000 0x80>;
		clocks = <&subclk>;
		alarms-count = <1>;
		status = "disabled";
	};

	drw: drw@444000 {
		compatible = "renesas,ra-drw";
		reg = <0x444000 0xd4>;
		status = "disabled";
	};
};

&nvic {
	arm,num-irq-priority-bits = <4>;
};
